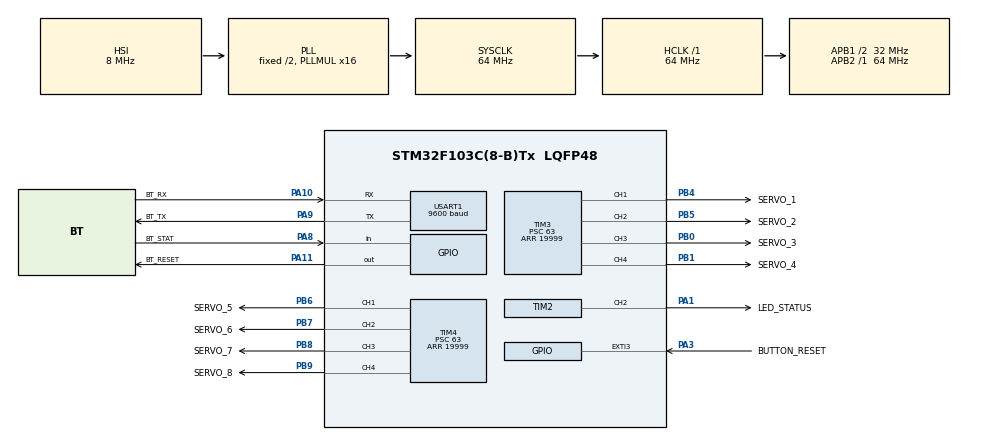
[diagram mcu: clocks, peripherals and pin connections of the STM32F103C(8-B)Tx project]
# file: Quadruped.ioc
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Dma.Request0=USART1_RX
Dma.USART1_RX.0.Direction=DMA_PERIPH_TO_MEMORY
Dma.USART1_RX.0.Instance=DMA1_Channel5
Dma.USART1_RX.0.MemDataAlignment=DMA_MDATAALIGN_BYTE
Dma.USART1_RX.0.MemInc=DMA_MINC_ENABLE
Dma.USART1_RX.0.Mode=DMA_NORMAL
Dma.USART1_RX.0.PeriphDataAlignment=DMA_PDATAALIGN_BYTE
Dma.USART1_RX.0.PeriphInc=DMA_PINC_DISABLE
Dma.USART1_RX.0.Priority=DMA_PRIORITY_LOW
Mcu.Family=STM32F1
Mcu.Name=STM32F103C(8-B)Tx
Mcu.Package=LQFP48
NVIC.DMA1_Channel5_IRQn=true\:0\:0\:false\:false\:true\:false\:true\:true
NVIC.EXTI3_IRQn=true\:0\:0\:false\:false\:true\:true\:true\:true
NVIC.PriorityGroup=NVIC_PRIORITYGROUP_4
NVIC.USART1_IRQn=true\:0\:0\:false\:false\:true\:true\:true\:true
PA1.GPIO_Label=LED_STATUS
PA1.Signal=S_TIM2_CH2
PA10.GPIO_Label=BT_RX
PA10.GPIO_PuPd=GPIO_PULLUP
PA10.Mode=Asynchronous
PA10.Signal=USART1_RX
PA11.GPIO_Label=BT_RESET
PA11.GPIO_PuPd=GPIO_PULLUP
PA11.GPIO_Speed=GPIO_SPEED_FREQ_HIGH
PA11.PinState=GPIO_PIN_SET
PA11.Signal=GPIO_Output
PA13.Mode=Serial_Wire
PA13.Signal=SYS_JTMS-SWDIO
PA14.Mode=Serial_Wire
PA14.Signal=SYS_JTCK-SWCLK
PA3.GPIO_Label=BUTTON_RESET
PA3.GPIO_ModeDefaultEXTI=GPIO_MODE_IT_FALLING
PA3.GPIO_PuPd=GPIO_PULLUP
PA3.Signal=GPXTI3
PA8.GPIO_Label=BT_STAT
PA8.GPIO_PuPd=GPIO_PULLUP
PA8.Signal=GPIO_Input
PA9.GPIO_Label=BT_TX
PA9.Mode=Asynchronous
PA9.Signal=USART1_TX
PB0.GPIO_Label=SERVO_3
PB0.Signal=S_TIM3_CH3
PB1.GPIO_Label=SERVO_4
PB1.Signal=S_TIM3_CH4
PB4.GPIO_Label=SERVO_1
PB4.Signal=S_TIM3_CH1
PB5.GPIO_Label=SERVO_2
PB5.Signal=S_TIM3_CH2
PB6.GPIO_Label=SERVO_5
PB6.Signal=S_TIM4_CH1
PB7.GPIO_Label=SERVO_6
PB7.Signal=S_TIM4_CH2
PB8.GPIO_Label=SERVO_7
PB8.Signal=S_TIM4_CH3
PB9.GPIO_Label=SERVO_8
PB9.Signal=S_TIM4_CH4
ProjectManager.HeapSize=0x200
ProjectManager.StackSize=0x400
ProjectManager.TargetToolchain=STM32CubeIDE
RCC.AHBFreq_Value=64000000
RCC.APB1CLKDivider=RCC_HCLK_DIV2
RCC.APB1Freq_Value=32000000
RCC.APB1TimFreq_Value=64000000
RCC.APB2Freq_Value=64000000
RCC.APB2TimFreq_Value=64000000
RCC.HCLKFreq_Value=64000000
RCC.PLLMUL=RCC_PLL_MUL16
RCC.SYSCLKFreq_VALUE=64000000
RCC.SYSCLKSource=RCC_SYSCLKSOURCE_PLLCLK
RCC.USBFreq_Value=64000000
SH.S_TIM2_CH2.0=TIM2_CH2,PWM Generation2 CH2
SH.S_TIM3_CH1.0=TIM3_CH1,PWM Generation1 CH1
SH.S_TIM3_CH2.0=TIM3_CH2,PWM Generation2 CH2
SH.S_TIM3_CH3.0=TIM3_CH3,PWM Generation3 CH3
SH.S_TIM3_CH4.0=TIM3_CH4,PWM Generation4 CH4
SH.S_TIM4_CH1.0=TIM4_CH1,PWM Generation1 CH1
SH.S_TIM4_CH2.0=TIM4_CH2,PWM Generation2 CH2
SH.S_TIM4_CH3.0=TIM4_CH3,PWM Generation3 CH3
SH.S_TIM4_CH4.0=TIM4_CH4,PWM Generation4 CH4
TIM2.Channel-PWM\ Generation2\ CH2=TIM_CHANNEL_2
TIM2.Period=63
TIM2.Prescaler=31
TIM3.Channel-PWM\ Generation1\ CH1=TIM_CHANNEL_1
TIM3.Channel-PWM\ Generation2\ CH2=TIM_CHANNEL_2
TIM3.Channel-PWM\ Generation3\ CH3=TIM_CHANNEL_3
TIM3.Channel-PWM\ Generation4\ CH4=TIM_CHANNEL_4
TIM3.Period=19999
TIM3.Prescaler=63
TIM4.Channel-PWM\ Generation1\ CH1=TIM_CHANNEL_1
TIM4.Channel-PWM\ Generation2\ CH2=TIM_CHANNEL_2
TIM4.Channel-PWM\ Generation3\ CH3=TIM_CHANNEL_3
TIM4.Channel-PWM\ Generation4\ CH4=TIM_CHANNEL_4
TIM4.Period=19999
TIM4.Prescaler=63
USART1.BaudRate=9600
USART1.VirtualMode=VM_ASYNC
VP_CRC_VS_CRC.Mode=CRC_Activate
VP_TIM2_VS_ClockSourceINT.Mode=Internal
VP_TIM3_VS_ClockSourceINT.Mode=Internal
VP_TIM4_VS_ClockSourceINT.Mode=Internal
board=custom

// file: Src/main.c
/* USER CODE BEGIN Header */
/**
  ******************************************************************************
  * @file           : main.c
  * @brief          : Main program body
  ******************************************************************************
  * @attention
  *
  * <h2><center>&copy; Copyright (c) 2019 STMicroelectronics.
  * All rights reserved.</center></h2>
  *
  * This software component is licensed by ST under BSD 3-Clause license,
  * the "License"; You may not use this file except in compliance with the
  * License. You may obtain a copy of the License at:
  *                        opensource.org/licenses/BSD-3-Clause
  *
  ******************************************************************************
  */
/* USER CODE END Header */
#include "main.h"

/* USER CODE BEGIN Includes */
#include "App/app.h"
/* USER CODE END Includes */

 CRC_HandleTypeDef hcrc;

TIM_HandleTypeDef htim2;
TIM_HandleTypeDef htim3;
TIM_HandleTypeDef htim4;

UART_HandleTypeDef huart1;
DMA_HandleTypeDef hdma_usart1_rx;

void SystemClock_Config(void);
static void MX_GPIO_Init(void);
static void MX_CRC_Init(void);
static void MX_TIM2_Init(void);
static void MX_TIM3_Init(void);
static void MX_DMA_Init(void);
static void MX_USART1_UART_Init(void);
static void MX_TIM4_Init(void);

int main(void)
{

  /* MCU Configuration--------------------------------------------------------*/

  /* Reset of all peripherals, Initializes the Flash interface and the Systick. */
  HAL_Init();

  /* Configure the system clock */
  SystemClock_Config();

  /* Initialize all configured peripherals */
  MX_GPIO_Init();
  MX_CRC_Init();
  MX_TIM2_Init();
  MX_TIM3_Init();
  MX_DMA_Init();
  MX_USART1_UART_Init();
  MX_TIM4_Init();
  /* USER CODE BEGIN 2 */
  App_Init();
  /* USER CODE END 2 */

  /* Infinite loop */
  /* USER CODE BEGIN WHILE */
  while (1)
  {
    App_Loop();
    /* USER CODE END WHILE */

  }
}

void SystemClock_Config(void)
{
  RCC_OscInitTypeDef RCC_OscInitStruct = {0};
  RCC_ClkInitTypeDef RCC_ClkInitStruct = {0};

  /** Initializes the RCC Oscillators according to the specified parameters
  * in the RCC_OscInitTypeDef structure.
  */
  RCC_OscInitStruct.OscillatorType = RCC_OSCILLATORTYPE_HSI;
  RCC_OscInitStruct.HSIState = RCC_HSI_ON;
  RCC_OscInitStruct.HSICalibrationValue = RCC_HSICALIBRATION_DEFAULT;
  RCC_OscInitStruct.PLL.PLLState = RCC_PLL_ON;
  RCC_OscInitStruct.PLL.PLLSource = RCC_PLLSOURCE_HSI_DIV2;
  RCC_OscInitStruct.PLL.PLLMUL = RCC_PLL_MUL16;
  if (HAL_RCC_OscConfig(&RCC_OscInitStruct) != HAL_OK)
  {
    Error_Handler();
  }

  /** Initializes the CPU, AHB and APB buses clocks
  */
  RCC_ClkInitStruct.ClockType = RCC_CLOCKTYPE_HCLK|RCC_CLOCKTYPE_SYSCLK
                              |RCC_CLOCKTYPE_PCLK1|RCC_CLOCKTYPE_PCLK2;
  RCC_ClkInitStruct.SYSCLKSource = RCC_SYSCLKSOURCE_PLLCLK;
  RCC_ClkInitStruct.AHBCLKDivider = RCC_SYSCLK_DIV1;
  RCC_ClkInitStruct.APB1CLKDivider = RCC_HCLK_DIV2;
  RCC_ClkInitStruct.APB2CLKDivider = RCC_HCLK_DIV1;

  if (HAL_RCC_ClockConfig(&RCC_ClkInitStruct, FLASH_LATENCY_2) != HAL_OK)
  {
    Error_Handler();
  }
}

static void MX_CRC_Init(void)
{

  hcrc.Instance = CRC;
  if (HAL_CRC_Init(&hcrc) != HAL_OK)
  {
    Error_Handler();
  }

}

static void MX_TIM2_Init(void)
{

  TIM_ClockConfigTypeDef sClockSourceConfig = {0};
  TIM_MasterConfigTypeDef sMasterConfig = {0};
  TIM_OC_InitTypeDef sConfigOC = {0};

  htim2.Instance = TIM2;
  htim2.Init.Prescaler = 31;
  htim2.Init.CounterMode = TIM_COUNTERMODE_UP;
  htim2.Init.Period = 63;
  htim2.Init.ClockDivision = TIM_CLOCKDIVISION_DIV1;
  htim2.Init.AutoReloadPreload = TIM_AUTORELOAD_PRELOAD_DISABLE;
  if (HAL_TIM_Base_Init(&htim2) != HAL_OK)
  {
    Error_Handler();
  }
  sClockSourceConfig.ClockSource = TIM_CLOCKSOURCE_INTERNAL;
  if (HAL_TIM_ConfigClockSource(&htim2, &sClockSourceConfig) != HAL_OK)
  {
    Error_Handler();
  }
  if (HAL_TIM_PWM_Init(&htim2) != HAL_OK)
  {
    Error_Handler();
  }
  sMasterConfig.MasterOutputTrigger = TIM_TRGO_RESET;
  sMasterConfig.MasterSlaveMode = TIM_MASTERSLAVEMODE_DISABLE;
  if (HAL_TIMEx_MasterConfigSynchronization(&htim2, &sMasterConfig) != HAL_OK)
  {
    Error_Handler();
  }
  sConfigOC.OCMode = TIM_OCMODE_PWM1;
  sConfigOC.Pulse = 0;
  sConfigOC.OCPolarity = TIM_OCPOLARITY_HIGH;
  sConfigOC.OCFastMode = TIM_OCFAST_DISABLE;
  if (HAL_TIM_PWM_ConfigChannel(&htim2, &sConfigOC, TIM_CHANNEL_2) != HAL_OK)
  {
    Error_Handler();
  }
  HAL_TIM_MspPostInit(&htim2);

}

static void MX_TIM3_Init(void)
{

  TIM_ClockConfigTypeDef sClockSourceConfig = {0};
  TIM_MasterConfigTypeDef sMasterConfig = {0};
  TIM_OC_InitTypeDef sConfigOC = {0};

  htim3.Instance = TIM3;
  htim3.Init.Prescaler = 63;
  htim3.Init.CounterMode = TIM_COUNTERMODE_UP;
  htim3.Init.Period = 19999;
  htim3.Init.ClockDivision = TIM_CLOCKDIVISION_DIV1;
  htim3.Init.AutoReloadPreload = TIM_AUTORELOAD_PRELOAD_DISABLE;
  if (HAL_TIM_Base_Init(&htim3) != HAL_OK)
  {
    Error_Handler();
  }
  sClockSourceConfig.ClockSource = TIM_CLOCKSOURCE_INTERNAL;
  if (HAL_TIM_ConfigClockSource(&htim3, &sClockSourceConfig) != HAL_OK)
  {
    Error_Handler();
  }
  if (HAL_TIM_PWM_Init(&htim3) != HAL_OK)
  {
    Error_Handler();
  }
  sMasterConfig.MasterOutputTrigger = TIM_TRGO_RESET;
  sMasterConfig.MasterSlaveMode = TIM_MASTERSLAVEMODE_DISABLE;
  if (HAL_TIMEx_MasterConfigSynchronization(&htim3, &sMasterConfig) != HAL_OK)
  {
    Error_Handler();
  }
  sConfigOC.OCMode = TIM_OCMODE_PWM1;
  sConfigOC.Pulse = 0;
  sConfigOC.OCPolarity = TIM_OCPOLARITY_HIGH;
  sConfigOC.OCFastMode = TIM_OCFAST_DISABLE;
  if (HAL_TIM_PWM_ConfigChannel(&htim3, &sConfigOC, TIM_CHANNEL_1) != HAL_OK)
  {
    Error_Handler();
  }
  if (HAL_TIM_PWM_ConfigChannel(&htim3, &sConfigOC, TIM_CHANNEL_2) != HAL_OK)
  {
    Error_Handler();
  }
  if (HAL_TIM_PWM_ConfigChannel(&htim3, &sConfigOC, TIM_CHANNEL_3) != HAL_OK)
  {
    Error_Handler();
  }
  if (HAL_TIM_PWM_ConfigChannel(&htim3, &sConfigOC, TIM_CHANNEL_4) != HAL_OK)
  {
    Error_Handler();
  }
  HAL_TIM_MspPostInit(&htim3);

}

static void MX_TIM4_Init(void)
{

  TIM_ClockConfigTypeDef sClockSourceConfig = {0};
  TIM_MasterConfigTypeDef sMasterConfig = {0};
  TIM_OC_InitTypeDef sConfigOC = {0};

  htim4.Instance = TIM4;
  htim4.Init.Prescaler = 63;
  htim4.Init.CounterMode = TIM_COUNTERMODE_UP;
  htim4.Init.Period = 19999;
  htim4.Init.ClockDivision = TIM_CLOCKDIVISION_DIV1;
  htim4.Init.AutoReloadPreload = TIM_AUTORELOAD_PRELOAD_DISABLE;
  if (HAL_TIM_Base_Init(&htim4) != HAL_OK)
  {
    Error_Handler();
  }
  sClockSourceConfig.ClockSource = TIM_CLOCKSOURCE_INTERNAL;
  if (HAL_TIM_ConfigClockSource(&htim4, &sClockSourceConfig) != HAL_OK)
  {
    Error_Handler();
  }
  if (HAL_TIM_PWM_Init(&htim4) != HAL_OK)
  {
    Error_Handler();
  }
  sMasterConfig.MasterOutputTrigger = TIM_TRGO_RESET;
  sMasterConfig.MasterSlaveMode = TIM_MASTERSLAVEMODE_DISABLE;
  if (HAL_TIMEx_MasterConfigSynchronization(&htim4, &sMasterConfig) != HAL_OK)
  {
    Error_Handler();
  }
  sConfigOC.OCMode = TIM_OCMODE_PWM1;
  sConfigOC.Pulse = 0;
  sConfigOC.OCPolarity = TIM_OCPOLARITY_HIGH;
  sConfigOC.OCFastMode = TIM_OCFAST_DISABLE;
  if (HAL_TIM_PWM_ConfigChannel(&htim4, &sConfigOC, TIM_CHANNEL_1) != HAL_OK)
  {
    Error_Handler();
  }
  if (HAL_TIM_PWM_ConfigChannel(&htim4, &sConfigOC, TIM_CHANNEL_2) != HAL_OK)
  {
    Error_Handler();
  }
  if (HAL_TIM_PWM_ConfigChannel(&htim4, &sConfigOC, TIM_CHANNEL_3) != HAL_OK)
  {
    Error_Handler();
  }
  if (HAL_TIM_PWM_ConfigChannel(&htim4, &sConfigOC, TIM_CHANNEL_4) != HAL_OK)
  {
    Error_Handler();
  }
  HAL_TIM_MspPostInit(&htim4);

}

static void MX_USART1_UART_Init(void)
{

  huart1.Instance = USART1;
  huart1.Init.BaudRate = 9600;
  huart1.Init.WordLength = UART_WORDLENGTH_8B;
  huart1.Init.StopBits = UART_STOPBITS_1;
  huart1.Init.Parity = UART_PARITY_NONE;
  huart1.Init.Mode = UART_MODE_TX_RX;
  huart1.Init.HwFlowCtl = UART_HWCONTROL_NONE;
  huart1.Init.OverSampling = UART_OVERSAMPLING_16;
  if (HAL_UART_Init(&huart1) != HAL_OK)
  {
    Error_Handler();
  }

}

static void MX_DMA_Init(void)
{

  /* DMA controller clock enable */
  __HAL_RCC_DMA1_CLK_ENABLE();

  /* DMA interrupt init */
  /* DMA1_Channel5_IRQn interrupt configuration */
  HAL_NVIC_SetPriority(DMA1_Channel5_IRQn, 0, 0);
  HAL_NVIC_EnableIRQ(DMA1_Channel5_IRQn);

}

static void MX_GPIO_Init(void)
{
  GPIO_InitTypeDef GPIO_InitStruct = {0};

  /* GPIO Ports Clock Enable */
  __HAL_RCC_GPIOA_CLK_ENABLE();
  __HAL_RCC_GPIOB_CLK_ENABLE();

  /*Configure GPIO pin Output Level */
  HAL_GPIO_WritePin(BT_RESET_GPIO_Port, BT_RESET_Pin, GPIO_PIN_SET);

  /*Configure GPIO pin : BUTTON_RESET_Pin */
  GPIO_InitStruct.Pin = BUTTON_RESET_Pin;
  GPIO_InitStruct.Mode = GPIO_MODE_IT_FALLING;
  GPIO_InitStruct.Pull = GPIO_PULLUP;
  HAL_GPIO_Init(BUTTON_RESET_GPIO_Port, &GPIO_InitStruct);

  /*Configure GPIO pin : BT_STAT_Pin */
  GPIO_InitStruct.Pin = BT_STAT_Pin;
  GPIO_InitStruct.Mode = GPIO_MODE_INPUT;
  GPIO_InitStruct.Pull = GPIO_PULLUP;
  HAL_GPIO_Init(BT_STAT_GPIO_Port, &GPIO_InitStruct);

  /*Configure GPIO pin : BT_RESET_Pin */
  GPIO_InitStruct.Pin = BT_RESET_Pin;
  GPIO_InitStruct.Mode = GPIO_MODE_OUTPUT_PP;
  GPIO_InitStruct.Pull = GPIO_PULLUP;
  GPIO_InitStruct.Speed = GPIO_SPEED_FREQ_HIGH;
  HAL_GPIO_Init(BT_RESET_GPIO_Port, &GPIO_InitStruct);

  /* EXTI interrupt init*/
  HAL_NVIC_SetPriority(EXTI3_IRQn, 0, 0);
  HAL_NVIC_EnableIRQ(EXTI3_IRQn);

}

void Error_Handler(void)
{
}
